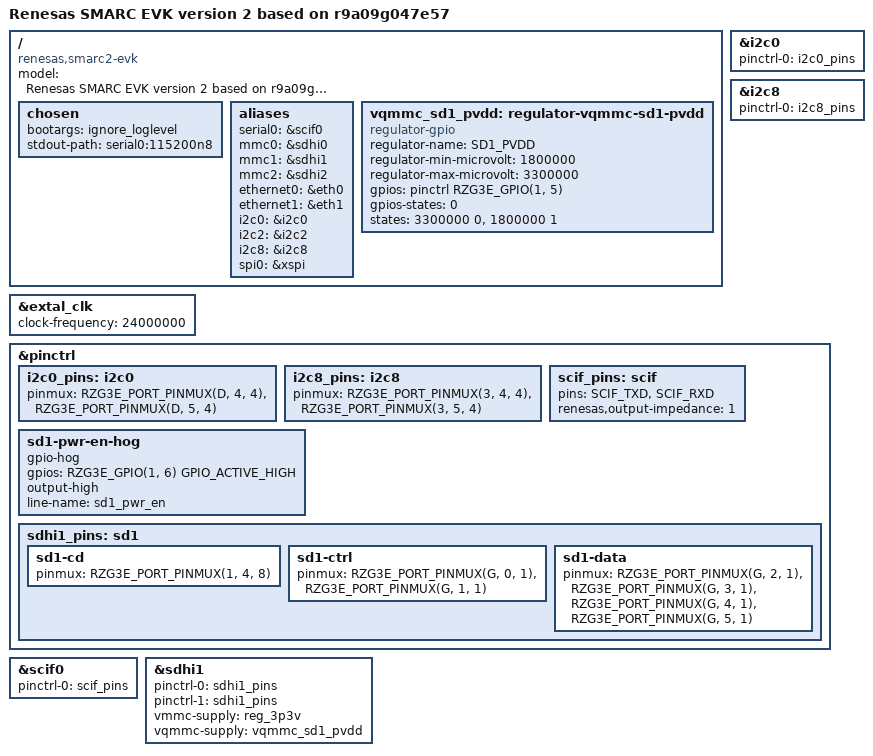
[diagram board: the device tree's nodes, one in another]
// SPDX-License-Identifier: (GPL-2.0-only OR BSD-2-Clause)
/*
 * Device Tree Source for the RZ/G3E SMARC EVK board
 * Based on Linux kernel 6.18 device tree for ARM SystemReady compliance.
 *
 * Copyright (C) 2024 Renesas Electronics Corp.
 */

/dts-v1/;

#include <dt-bindings/gpio/gpio.h>
#include <dt-bindings/pinctrl/renesas,r9a09g047-pinctrl.h>
#include "r9a09g047.dtsi"
#include "r9a09g047-u-boot.dtsi"
#include "rzg3e-smarc-som.dtsi"
#include "renesas-smarc2.dtsi"

/ {
	model = "Renesas SMARC EVK version 2 based on r9a09g047e57";
	compatible = "renesas,smarc2-evk", "renesas,rzg3e-smarcm",
		     "renesas,r9a09g047e57", "renesas,r9a09g047";

	/* Override chosen for U-Boot */
	chosen {
		bootargs = "ignore_loglevel";
		stdout-path = "serial0:115200n8";
	};

	/* Override aliases for proper device ordering */
	aliases {
		serial0 = &scif0;
		mmc0 = &sdhi0;
		mmc1 = &sdhi1;
		mmc2 = &sdhi2;
		ethernet0 = &eth0;
		ethernet1 = &eth1;
		i2c0 = &i2c0;
		i2c2 = &i2c2;
		i2c8 = &i2c8;
		spi0 = &xspi;
	};

	vqmmc_sd1_pvdd: regulator-vqmmc-sd1-pvdd {
		compatible = "regulator-gpio";
		regulator-name = "SD1_PVDD";
		regulator-min-microvolt = <1800000>;
		regulator-max-microvolt = <3300000>;
		gpios = <&pinctrl RZG3E_GPIO(1, 5) GPIO_ACTIVE_HIGH>;
		gpios-states = <0>;
		states = <3300000 0>, <1800000 1>;
	};
};

/* Override extal_clk frequency */
&extal_clk {
	clock-frequency = <24000000>;
};

&i2c0 {
	pinctrl-0 = <&i2c0_pins>;
	pinctrl-names = "default";
};

&i2c8 {
	pinctrl-0 = <&i2c8_pins>;
	pinctrl-names = "default";
	status = "okay";
};

&pinctrl {
	i2c0_pins: i2c0 {
		pinmux = <RZG3E_PORT_PINMUX(D, 4, 4)>, /* SCL0 */
			 <RZG3E_PORT_PINMUX(D, 5, 4)>; /* SDA0 */
	};

	i2c8_pins: i2c8 {
		pinmux = <RZG3E_PORT_PINMUX(3, 4, 4)>, /* SCL8 */
			 <RZG3E_PORT_PINMUX(3, 5, 4)>; /* SDA8 */
	};

	scif_pins: scif {
		pins = "SCIF_TXD", "SCIF_RXD";
		renesas,output-impedance = <1>;
	};

	sd1-pwr-en-hog {
		gpio-hog;
		gpios = <RZG3E_GPIO(1, 6) GPIO_ACTIVE_HIGH>;
		output-high;
		line-name = "sd1_pwr_en";
	};

	sdhi1_pins: sd1 {
		sd1-cd {
			pinmux = <RZG3E_PORT_PINMUX(1, 4, 8)>; /* SD1CD */
		};

		sd1-ctrl {
			pinmux = <RZG3E_PORT_PINMUX(G, 0, 1)>, /* SD1CLK */
				 <RZG3E_PORT_PINMUX(G, 1, 1)>; /* SD1CMD */
		};

		sd1-data {
			pinmux = <RZG3E_PORT_PINMUX(G, 2, 1)>, /* SD1DAT0 */
				 <RZG3E_PORT_PINMUX(G, 3, 1)>, /* SD1DAT1 */
				 <RZG3E_PORT_PINMUX(G, 4, 1)>, /* SD1DAT2 */
				 <RZG3E_PORT_PINMUX(G, 5, 1)>; /* SD1DAT3 */
		};
	};
};

&scif0 {
	pinctrl-0 = <&scif_pins>;
	pinctrl-names = "default";
};

&sdhi1 {
	pinctrl-0 = <&sdhi1_pins>;
	pinctrl-1 = <&sdhi1_pins>;
	pinctrl-names = "default", "state_uhs";

	vmmc-supply = <&reg_3p3v>;
	vqmmc-supply = <&vqmmc_sd1_pvdd>;
};
